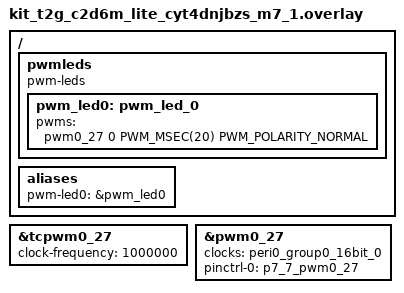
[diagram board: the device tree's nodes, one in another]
/*
 * SPDX-FileCopyrightText: Copyright (c) 2026 Infineon Technologies AG,
 * SPDX-FileCopyrightText: or an affiliate of Infineon Technologies AG. All rights reserved.
 * SPDX-FileCopyrightText: Copyright (c) 2026 Linumiz
 *
 * SPDX-License-Identifier: Apache-2.0
 */

#include <zephyr/dt-bindings/pwm/pwm.h>
#include "kit_t2g_c2d6m_lite_common.overlay"

/ {
	pwmleds {
		compatible = "pwm-leds";

		pwm_led0: pwm_led_0 {
			pwms = <&pwm0_27 0 PWM_MSEC(20) PWM_POLARITY_NORMAL>;
		};
	};

	aliases {
		pwm-led0 = &pwm_led0;
	};
};

&tcpwm0_27 {
	clock-frequency = <1000000>;
	status = "okay";
};

&pwm0_27 {
	clocks = <&peri0_group0_16bit_0>;
	pinctrl-0 = <&p7_7_pwm0_27>;
	pinctrl-names = "default";
	status = "okay";
};
